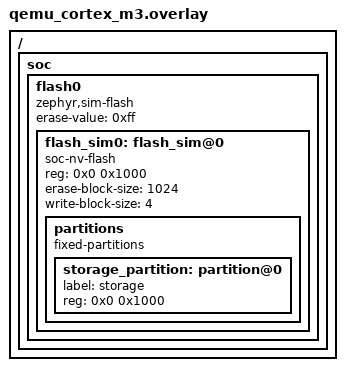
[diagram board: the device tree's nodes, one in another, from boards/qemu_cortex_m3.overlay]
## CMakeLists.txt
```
cmake_minimum_required(VERSION 3.20.0)

find_package(Zephyr REQUIRED HINTS $ENV{ZEPHYR_BASE})
project(test)

add_compile_definitions(CONFIG_CTR_CLOUD_LOG_LEVEL=4)
add_compile_definitions(CONFIG_CTR_CLOUD_TRANSFER_BUF_SIZE=16384)

include_directories(${CMAKE_CURRENT_SOURCE_DIR}/../../../subsys/ctr_cloud)
target_sources(app PRIVATE ${CMAKE_CURRENT_SOURCE_DIR}/../../../subsys/ctr_cloud/ctr_cloud_packet.c)
target_sources(app PRIVATE ${CMAKE_CURRENT_SOURCE_DIR}/../../../subsys/ctr_cloud/ctr_cloud_msg.c)
target_sources(app PRIVATE ${CMAKE_CURRENT_SOURCE_DIR}/../../../subsys/ctr_cloud/ctr_cloud_transfer.c)
target_sources(app PRIVATE ${CMAKE_CURRENT_SOURCE_DIR}/../../../subsys/ctr_cloud/ctr_cloud_util.c)
target_sources(app PRIVATE ${CMAKE_CURRENT_SOURCE_DIR}/../../../subsys/ctr_cloud/ctr_cloud_process.c)
target_sources(app PRIVATE ${CMAKE_CURRENT_SOURCE_DIR}/../../../subsys/ctr_cloud/ctr_cloud_shell.c)
target_sources(app PRIVATE ${CMAKE_CURRENT_SOURCE_DIR}/../../../subsys/ctr_cloud/ctr_cloud.c)

target_sources(app PRIVATE src/mock.c)
target_sources(app PRIVATE src/mock_ctr_info.c)
target_sources(app PRIVATE src/mock_ctr_lte_v2.c)
target_sources(app PRIVATE src/mock_ctr_rtc.c)

target_sources(app PRIVATE src/test_packet.c)
target_sources(app PRIVATE src/test_msg.c)

# target_sources(app PRIVATE src/test_cloud.c)
```

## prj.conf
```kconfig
CONFIG_LOG=y

CONFIG_EVENTS=y

CONFIG_SHELL=y
CONFIG_SHELL_LOG_BACKEND=n
CONFIG_SHELL_BACKEND_SERIAL=n
CONFIG_SHELL_BACKEND_DUMMY=y
CONFIG_SHELL_CMD_BUFF_SIZE=90
CONFIG_SHELL_BACKEND_DUMMY_BUF_SIZE=4096

CONFIG_CTR_BUF=y
CONFIG_CTR_UTIL=y
CONFIG_CTR_CONFIG=y
CONFIG_CTR_CONFIG_FACTORY_RESET=n
CONFIG_BASE64=y

CONFIG_SETTINGS=y
CONFIG_SETTINGS_FILE=y

CONFIG_ZCBOR=y
CONFIG_ZCBOR_STOP_ON_ERROR=y
CONFIG_ZCBOR_VERBOSE=n

CONFIG_ZTEST=y

CONFIG_HEAP_MEM_POOL_SIZE=256
CONFIG_MAIN_STACK_SIZE=2048

CONFIG_REBOOT=y

# PSA crypto API (backend selection is per-board; see boards/*.conf)
CONFIG_PSA_WANT_ALG_SHA_256=y
```

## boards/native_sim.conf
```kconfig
CONFIG_FLASH_SIMULATOR=y
CONFIG_FLASH=y
CONFIG_FLASH_MAP=y

# native_sim has a CSPRNG-capable entropy driver, so the Mbed TLS PSA
# provider works without the external-RNG fallback. On this non-Nordic target
# PSA_CRYPTO selects the Mbed TLS provider (CONFIG_PSA_CRYPTO_PROVIDER_MBEDTLS).
CONFIG_PSA_CRYPTO=y
CONFIG_ENTROPY_GENERATOR=y
```

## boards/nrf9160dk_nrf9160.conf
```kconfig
CONFIG_FLASH=y
CONFIG_FLASH_MAP=y

# nRF targets use the nRF Security PSA backend (CryptoCell / Oberon).
# On Nordic ARM, PSA_CRYPTO selects CONFIG_PSA_CRYPTO_PROVIDER_CUSTOM, which
# auto-enables NRF_SECURITY and MBEDTLS_PSA_CRYPTO_C.
CONFIG_PSA_CRYPTO=y
```

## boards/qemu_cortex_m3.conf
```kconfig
CONFIG_FLASH_SIMULATOR=y
CONFIG_FLASH=y
CONFIG_FLASH_MAP=y

# qemu_cortex_m3 has no CSPRNG / entropy driver, so use the Mbed TLS PSA
# provider with the external (non-CSPRNG) RNG. This is fine for tests.
CONFIG_PSA_CRYPTO=y
CONFIG_MBEDTLS_PSA_CRYPTO_EXTERNAL_RNG=y
CONFIG_MBEDTLS_PSA_CRYPTO_EXTERNAL_RNG_ALLOW_NON_CSPRNG=y
CONFIG_TEST_RANDOM_GENERATOR=y
```

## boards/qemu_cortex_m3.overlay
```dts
/ {
	soc {
		flash0 {
			compatible = "zephyr,sim-flash";
			status = "okay";
			erase-value = <0xff>;
			#address-cells = <1>;
			#size-cells = <1>;

			flash_sim0: flash_sim@0 {
				compatible = "soc-nv-flash";
				reg = <0x0 0x1000>;

				erase-block-size = <1024>;
				write-block-size = <4>;

				partitions {
					compatible = "fixed-partitions";
					#address-cells = <1>;
					#size-cells = <1>;

					storage_partition: partition@0 {
						label = "storage";
						reg = <0x0 0x1000>;
					};
				};
			};
		};
	};
};
```

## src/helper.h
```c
#ifndef TESTS_SUBSYS_CTR_CLOUD_SRC_HELPER_H_
#define TESTS_SUBSYS_CTR_CLOUD_SRC_HELPER_H_

#define PRINT_CTR_BUF(_name)                                                                       \
	printf("buffer: ");                                                                        \
	for (int i = 0; i < _name.len; i++) {                                                      \
		printf("%02x", _name.mem[i]);                                                      \
	}                                                                                          \
	printf("\n");

#endif
```

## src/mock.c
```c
#include "mock.h"

/* Standard includes */
#include <ctype.h>
#include <stdbool.h>
#include <stdlib.h>
#include <string.h>

/* Zephyr includes */
#include <zephyr/kernel.h>
#include <zephyr/settings/settings.h>
#include <zephyr/shell/shell.h>
#include <zephyr/shell/shell_dummy.h>
#include <zephyr/ztest.h>

/* Chester includes */
#include <chester/ctr_config.h>

struct app_config {
	int interval_sample;
	int interval_report;
	bool backup_report_connected;
};

static struct app_config m_app_config_interim = {
	.interval_sample = 5,
	.interval_report = 60,
	.backup_report_connected = false,
};

// void sys_arch_reboot(int type)
// {
// 	printf("sys_arch_reboot: %d\n", type);
// }

static int app_config_cmd_config_show(const struct shell *shell, size_t argc, char **argv)
{
	shell_print(shell, "app config interval-sample %d", m_app_config_interim.interval_sample);
	shell_print(shell, "app config interval-report %d", m_app_config_interim.interval_report);
	shell_print(shell, "app config backup-report-connected %s",
		    m_app_config_interim.backup_report_connected ? "true" : "false");
	return 0;
}

void *mock_global_setup_suite(void)
{
	static bool is_setup = false;

	printf("mock_global_setup_suite: %d\n", is_setup);

	if (is_setup) {
		return NULL;
	}

	// Wait for the initialization of the shell dummy backend
	const struct shell *sh = shell_backend_dummy_get_ptr();
	WAIT_FOR(shell_ready(sh), 20000, k_msleep(1));
	zassert_true(shell_ready(sh), "timed out waiting for dummy shell backend");

	// Register callbacks for the `config show` command
	ctr_config_append_show("app", app_config_cmd_config_show);

	is_setup = true;

	return NULL;
}

int app_config_cmd_config_interval_sample(const struct shell *shell, size_t argc, char **argv)
{
	if (argc == 2) {
		int interval_sample = atoi(argv[1]);

		if (interval_sample < 5 || interval_sample > 3600) {
			shell_error(shell, "invalid range");
			return -EINVAL;
		}

		m_app_config_interim.interval_sample = interval_sample;

		return 0;
	}

	shell_help(shell);
	return -EINVAL;
}

int app_config_cmd_config_interval_report(const struct shell *shell, size_t argc, char **argv)
{
	if (argc == 2) {
		int interval_report = atoi(argv[1]);

		if (interval_report < 30 || interval_report > 86400) {
			shell_error(shell, "invalid range");
			return -EINVAL;
		}

		m_app_config_interim.interval_report = interval_report;

		return 0;
	}

	shell_help(shell);
	return -EINVAL;
}

int app_config_cmd_config_backup_report_connected(const struct shell *shell, size_t argc,
						  char **argv)
{
	if (argc == 2) {
		bool is_false = !strcmp(argv[1], "false");
		bool is_true = !strcmp(argv[1], "true");

		if (is_false) {
			m_app_config_interim.backup_report_connected = false;
		} else if (is_true) {
			m_app_config_interim.backup_report_connected = true;
		} else {
			shell_error(shell, "invalid format");
			return -EINVAL;
		}

		return 0;
	}

	shell_help(shell);
	return -EINVAL;
}

static int print_help(const struct shell *shell, size_t argc, char **argv)
{
	if (argc > 1) {
		shell_error(shell, "command not found: %s", argv[1]);
		shell_help(shell);
		return -EINVAL;
	}

	shell_help(shell);

	return 0;
}

SHELL_STATIC_SUBCMD_SET_CREATE(
	sub_app_config,

	SHELL_CMD_ARG(show, NULL, "List current configuration.", app_config_cmd_config_show, 1, 0),

	SHELL_CMD_ARG(interval-sample, NULL,
		      "Get/Set sample interval in seconds (format: <5-3600>).",
		      app_config_cmd_config_interval_sample, 1, 1),

	SHELL_CMD_ARG(interval-report, NULL,
		      "Get/Set report interval in seconds (format: <30-86400>).",
		      app_config_cmd_config_interval_report, 1, 1),

	SHELL_CMD_ARG(backup-report-connected, NULL,
		      "Get/Set report when backup is active (format: true, false).",
		      app_config_cmd_config_backup_report_connected, 1, 1),

	SHELL_SUBCMD_SET_END);

SHELL_STATIC_SUBCMD_SET_CREATE(sub_app,

			       SHELL_CMD_ARG(config, &sub_app_config, "Configuration commands.",
					     print_help, 1, 0),

			       SHELL_SUBCMD_SET_END);

SHELL_CMD_REGISTER(app, &sub_app, "Application commands.", print_help);
```

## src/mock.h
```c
#ifndef TESTS_SUBSYS_CTR_CLOUD_SRC_MOCK_H_
#define TESTS_SUBSYS_CTR_CLOUD_SRC_MOCK_H_

void *mock_global_setup_suite(void);

void mock_ctr_lte_v2_set_send_recv(char **list, int size);

#endif
```

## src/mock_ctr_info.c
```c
#include <chester/ctr_info.h>

int ctr_info_get_vendor_name(char **vendor_name)
{
	static char name[] = "HARDWARIO";
	*vendor_name = name;
	return 0;
}

int ctr_info_get_product_name(char **product_name)
{
	static char name[] = "CHESTER-M";
	*product_name = name;
	return 0;
}

int ctr_info_get_hw_variant(char **hw_variant)
{
	static char variant[] = "CGLS";
	*hw_variant = variant;
	return 0;
}
int ctr_info_get_hw_revision(char **hw_revision)
{
	static char revision[] = "R3.2";
	*hw_revision = revision;
	return 0;
}

int ctr_info_get_fw_bundle(char **fw_bundle)
{
	static char bundle[] = "com.hardwario.mockup-app";
	*fw_bundle = bundle;
	return 0;
}

int ctr_info_get_fw_name(char **fw_name)
{
	static char name[] = "mockup-app";
	*fw_name = name;
	return 0;
}

int ctr_info_get_fw_version(char **fw_version)
{
	static char version[] = "v0.0.1";
	*fw_version = version;
	return 0;
}

int ctr_info_get_serial_number_uint32(uint32_t *serial_number)
{
	*serial_number = 2159017985;
	return 0;
}

int ctr_info_get_claim_token(char **claim_token)
{
	static char token[] = "98a8856ba6534bd5212176b22f3acbb3";
	*claim_token = token;
	return 0;
}

int ctr_info_get_ble_passkey(char **ble_passkey)
{
	static char passkey[] = "654123";
	*ble_passkey = passkey;
	return 0;
}
```

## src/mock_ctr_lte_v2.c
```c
#include "mock.h"

#include <zephyr/kernel.h>
#include <zephyr/ztest.h>

#include <chester/ctr_buf.h>
#include <chester/ctr_lte_v2.h>
#include <ctr_cloud_packet.h>

static bool is_enabled = false;

int ctr_lte_v2_enable(void)
{
	is_enabled = true;
	return 0;
}

int ctr_lte_v2_wait_for_connected(k_timeout_t timeout)
{
	if (!is_enabled) {
		return -1;
	}

	return 0;
}

int ctr_lte_v2_get_imei(uint64_t *imei)
{
	*imei = 987654321098761;
	return 0;
}

int ctr_lte_v2_get_imsi(uint64_t *imsi)
{
	*imsi = 123456789012341;
	return 0;
}

int ctr_lte_v2_get_iccid(char **iccid)
{
	static char iccid_str[] = "89882390000262826558";
	*iccid = iccid_str;
	return 0;
}

int ctr_lte_v2_get_modem_fw_version(char **version)
{
	*version = "v1.5.0";
	return 0;
}

void print_bufer(uint8_t *buf, size_t len)
{
	for (int i = 0; i < len; i++) {
		printf("%02x", buf[i]);
	}
	printf("\n");
}

static struct {
	int index;
	int size;
	char **list;

	uint8_t recv[CTR_CLOUD_PACKET_MAX_SIZE];
} mock_com;

void mock_ctr_lte_v2_set_send_recv(char **list, int size)
{
	mock_com.index = 0;
	mock_com.size = size;
	mock_com.list = list;
}

int ctr_lte_v2_send_recv(const struct ctr_lte_v2_send_recv_param *param)
{
	printf("mock: ctr_lte_v2_send_recv %d\n", mock_com.index);

	for (size_t i = 0; i < param->send_len; i++) {
		printf("%02x", ((uint8_t *)param->send_buf)[i]);
	}
	printf("\n");

	if (mock_com.index >= mock_com.size) {
		return -1;
	}

	char *recvStr = mock_com.list[mock_com.index++];

	hex2bin(recvStr, strlen(recvStr), mock_com.recv, sizeof(mock_com.recv));

	zassert_mem_equal(mock_com.recv, param->send_buf, param->send_len, NULL);

	char *sendStr = mock_com.list[mock_com.index++];
	*param->recv_len = 0;

	if (sendStr != NULL && param->recv_buf) {
		*param->recv_len =
			hex2bin(sendStr, strlen(sendStr), param->recv_buf, param->recv_size);
	}

	return 0;
}

int ctr_lte_v2_get_conn_param(struct ctr_lte_v2_conn_param *param)
{
	param->valid = true;
	param->result = 0;
	param->ecl = 12;
	param->rsrp = 13;
	param->rsrq = 14;
	param->snr = 15;
	param->plmn = 16;
	param->cid = 17;
	param->band = 18;
	param->earfcn = 19;
	return 0;
}
```

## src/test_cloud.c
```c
/** @file
 *  @brief cloud transfere test suite
 */

#include "mock.h"

#include <zephyr/kernel.h>
#include <zephyr/settings/settings.h>
#include <zephyr/ztest.h>
#include <zephyr/shell/shell.h>
#include <zephyr/shell/shell_dummy.h>

#include <chester/ctr_buf.h>
#include <chester/ctr_cloud.h>
#include <ctr_cloud_packet.h>
#include <ctr_cloud_msg.h>
#include <ctr_cloud_util.h>

ZTEST(subsus_ctr_cloud_2_cloud, test_boot)
{
	int ret;

	static char *comunication[] = {
		// send: Sequence: 0 [FLxx] len: 128 / upload session
		"422941fa2c33723f80b00001c00000bf0000101a80b00001016948415244574152494f026943484553"
		"5445522d4d036443474c53046452332e32057818636f6d2e68617264776172696f2e6d6f636b75702d"
		"617070066a6d6f636b75702d617070076676302e302e3108663635343132330a1b0003824430f85009"
		"091b00007048860ddf750b6676312e352e30ff",
		// recv: Sequence: 1 [xxAP] len: 0 / ack + signal poll
		"49247ac38dacbbf280b000013001",
		// send: Sequence: 2 [xxxP] len: 0 / poll
		"98b2f3d80b97ac9280b000011002",
		// recv: Sequence: 3 [FLxx] len: 73 / download session
		"9d810702bd57739980b00001c00380a4001a64ba538f041a64ba538e05782430313838643835632d38"
		"3936322d373836662d633938352d6136376665653762623134340672746573742d6465766963652d73"
		"302d393835",
		// send: Sequence: 4 [xxAx] len: 0 / ack
		"7cf1efb80c99381780b000012004",
		// no recv
		NULL,
		// send: Sequence: 5 [FLxx] len: 115 / upload config
		"ffd664838db07ee980b00001c0050273a9151b127641bb009f781c61707020636f6e66696720696e74"
		"657276616c2d73616d706c652035781d61707020636f6e66696720696e74657276616c2d7265706f72"
		"74203630782861707020636f6e666967206261636b75702d7265706f72742d636f6e6e656374656420"
		"66616c7365ff",
		// recv: equence: 6 [xxAP] len: 0 / ack + signal poll
		"0842b756691c629f80b000013006",
		// send: Sequence: 7 [xxxP] len: 0 / poll
		"945af7019589847480b000011007",
		// recv: Sequence: 8 [FLxx] len: 106 / download config
		"d2ea74f6a898857880b00001c008820083781d61707020636f6e66696720696e74657276616c2d7361"
		"6d706c65203130781d61707020636f6e66696720696e74657276616c2d7265706f7274203630782761"
		"707020636f6e666967206261636b75702d7265706f72742d636f6e6e65637465642074727565",
		// send: Sequence: 9 [xxAx] len: 0 / ack
		"80e388a08e84beb080b000012009",
		// no recv
		NULL,
		// send: Sequence: 10 [xxxP] len: 0
		"cb4bb2d99e3a56e680b00001100a",
		// recv: Sequence: 11 [FLxx] len: 0
		"7bc147fda33d7aee80b00001c00b",
		// send: packet Sequence: 12 [xxxP] len: 0
		"ae81ae8eeedbd27180b00001100c",
		// recv: Sequence: 13 [FLxx] len: 66 / download shell
		"76e10e221e84573080b00001c00d87a200826f61707020636f6e6669672073686f77781a6170702063"
		"6f6e66696720696e74657276616c2d73616d706c650150018dd0f29d0175f2abaf092b8d2f9f2b",
		// send: Sequence: 14 [xxAx] len: 0
		"5eded0b6ce8631e880b00001200e",
		NULL,
		// send: Sequence: 15 [FLxx] len: 259 / upload shell
		"327c0f4de53ae7ed80b00001c00f07bf0150018dd0f29d0175f2abaf092b8d2f9f2b009fbf006f6170"
		"7020636f6e6669672073686f77029f781d61707020636f6e66696720696e74657276616c2d73616d70"
		"6c65203130781d61707020636f6e66696720696e74657276616c2d7265706f72742036307827617070"
		"20636f6e666967206261636b75702d7265706f72742d636f6e6e65637465642074727565ffffbf0078"
		"1a61707020636f6e66696720696e74657276616c2d73616d706c650135029f7848696e74657276616c"
		"2d73616d706c65202d204765742f5365742073616d706c6520696e74657276616c20696e207365636f"
		"6e64732028666f726d61743a203c352d333630303e292effffffff",
		// recv: Sequence: 16 [xxAx] len: 0
		"ca3e3abdaf98f36880b000012010",
		NULL,
	};

	mock_ctr_lte_v2_set_send_recv(comunication, sizeof(comunication) / sizeof(comunication[0]));

	static struct ctr_cloud_options options = {
		.decoder_hash = 0,
		.encoder_hash = 0,
		.decoder_buf = NULL,
		.decoder_len = 0,
		.encoder_buf = NULL,
		.encoder_len = 0,
	};

	int64_t ts;

	// ret = ctr_cloud_get_last_seen_ts(&ts);
	// zassert_equal(ret, -EPERM, "ctr_cloud_get_last_seen_ts failed");

	ret = ctr_cloud_init(&options);
	zassert_ok(ret, "ctr_cloud_init failed");

	ret = ctr_cloud_wait_initialized(K_MSEC(2000));
	zassert_ok(ret, "ctr_cloud_wait_initialized failed");

	ret = ctr_cloud_get_last_seen_ts(&ts);
	zassert_ok(ret, "ctr_cloud_get_last_seen_ts");

	zassert_equal(ts, 1689932686, "last downlink ts");

	printf("\ntest: last downlink ts: %lld\n", ts);

	ctr_cloud_downlink(K_FOREVER); // poll without data
	ctr_cloud_downlink(K_FOREVER); // poll shell

	k_sleep(K_MSEC(300));
}

// ZTEST(subsus_ctr_cloud_2_cloud, test_app_fw)
// {
// 	int ret;

// 	static char *comunication[] = {
// 		// send: Sequence: 0 [FLxx] len: 128 / upload session
// 		"422941fa2c33723f80b00001c00000bf0000101a80b00001016948415244574152494f026943484553"
// 		"5445522d4d036443474c53046452332e32057818636f6d2e68617264776172696f2e6d6f636b75702d"
// 		"617070066a6d6f636b75702d617070076676302e302e3108663635343132330a1b0003824430f85009"
// 		"091b00007048860ddf750b6676312e352e30ff",
// 		// recv: Sequence: 1 [xxAP] len: 0 / ack + signal poll
// 		"49247ac38dacbbf280b000013001",
// 		// send: Sequence: 2 [xxxP] len: 0 / poll
// 		"98b2f3d80b97ac9280b000011002",
// 		// recv: Sequence: 3 [FLxx] len: 93 / download session
// 		"ea9c3efa69351cef80b00001c00380a6001a65e62f3d021b46c3ba674e0f604f031b73a9151b127641"
// 		"bb041a65e62f3c05782430313838643835632d383936322d373836662d633938352d61363766656537"
// 		"62623134340672746573742d6465766963652d73302d393835",
// 		// send: Sequence: 4 [xxAx] len: 0 / ack
// 		"7cf1efb80c99381780b000012004",
// 		// no recv
// 		NULL,
// 		// Sequence: 5 [xxxP] len: 0
// 		"8518c99e482c211680b000011005",
// 		// Sequence: 6 [FLxx] len: 0
// 		"fdca48f52dcd34e580b00001c006",
// 		// Sequence: 7 [FLxx] len: 57 / upload firmware app start
// 		"d525afc2f3d822eb80b00001c00708bf00636170700168646f776e6c6f616404193f00057820613861"
// 		"3839663530386130383462323239393634316266346135306636356564ff",
// 		// Sequence: 8 [xxAP] len: 0
// 		"f595fffcda87190080b000013008",
// 		// Sequence: 9 [xxxP] len: 0
// 		"e4033647654ea95f80b000011009",
// 		// Sequence: 10 [FLxx] len: 73 // download firmware chunk offset 0
// 		"2f378122505c8de480b00001c00a88a7006361707001656368756e6b0250018e39b69e7d73d68497b2"
// 		"9fb053ba20030004181e05581eaabbccddee00112233445566778899aabbccddee0011223344556677"
// 		"889906181e",
// 		// Sequence: 11 [xxAx] len: 0
// 		"c858daa739bdd2fb80b00001200b",
// 		// no recv
// 		NULL,
// 	};
// 	mock_ctr_lte_v2_set_send_recv(comunication, sizeof(comunication) / sizeof(comunication[0]));

// 	static struct ctr_cloud_options options = {
// 		.decoder_hash = 0,
// 		.encoder_hash = 0,
// 		.decoder_buf = NULL,
// 		.decoder_len = 0,
// 		.encoder_buf = NULL,
// 		.encoder_len = 0,
// 	};

// 	ret = ctr_cloud_init(&options);
// 	zassert_ok(ret, "ctr_cloud_init failed");

// 	ret = ctr_cloud_wait_initialized(K_MSEC(2000));
// 	zassert_ok(ret, "ctr_cloud_wait_initialized failed");

// 	ctr_cloud_recv(); // poll without data

// 	const struct shell *sh = shell_backend_dummy_get_ptr();
// 	shell_backend_dummy_clear_output(sh);
// 	ret = shell_execute_cmd(sh, "cloud firmware download a8a89f508a084b2299641bf4a50f65ed");
// 	// zassert_ok(ret, "shell_execute_cmd failed");
// 	size_t size;
// 	const char *p = shell_backend_dummy_get_output(sh, &size);
// 	zassert_not_null(p, "shell_backend_dummy_get_output failed");

// 	printf("\n%s\n", p);

// 	k_sleep(K_MSEC(500));
// }

ZTEST_SUITE(subsus_ctr_cloud_2_cloud, NULL, mock_global_setup_suite, NULL, NULL, NULL);
```

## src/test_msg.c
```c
/** @file
 *  @brief cloud message test suite
 *
 */

#include "helper.h"
#include "mock.h"

#include <zephyr/kernel.h>
#include <zephyr/ztest.h>
#include <zephyr/settings/settings.h>

#include <chester/ctr_buf.h>
#include <ctr_cloud_msg.h>
#include <ctr_cloud_util.h>

ZTEST(subsus_ctr_cloud_1_msg, test_pack_create_session)
{
	CTR_BUF_DEFINE(buffer, 512);

	int ret = ctr_cloud_msg_pack_create_session(&buffer);
	zassert_ok(ret, "ctr_cloud_msg_pack_create_session failed");

	char *expectHex =
		"00bf0000101a80b00001016948415244574152494f0269434845535445522d4d036443474c53046452"
		"332e32057818636f6d2e68617264776172696f2e6d6f636b75702d617070066a6d6f636b75702d6170"
		"70076676302e302e3108663635343132330a1b0003824430f85009091b00007048860ddf7511743839"
		"3838323339303030303236323832363535380b6676312e352e30ff";

	// PRINT_CTR_BUF(buffer);

	CTR_BUF_DEFINE(expect, 512);

	expect.len = hex2bin(expectHex, strlen(expectHex), expect.mem, expect.size);

	zassert_equal(buffer.len, expect.len, "len equal");
	zassert_mem_equal(buffer.mem, expect.mem, expect.len, "mem equal");
}

ZTEST(subsus_ctr_cloud_1_msg, test_unpack_set_session)
{
	CTR_BUF_DEFINE(buffer, 512);

	char *input = "80a6001a649e9358011b1fbe3ac758c6f88c021b46c3ba674e0f604f041a649e935905782430"
		      "313839306236362d633866352d373065612d396634332d61666532346564663966353506696b"
		      "6172656c2d646576";

	buffer.len = hex2bin(input, strlen(input), buffer.mem, buffer.size);

	struct ctr_cloud_session session;

	int ret = ctr_cloud_msg_unpack_set_session(&buffer, &session);
	zassert_ok(ret, "ctr_cloud_msg_unpack_set_session failed");

	zassert_equal(session.id, (uint32_t)1688114008, "id");
	zassert_equal(session.decoder_hash, (uint64_t)0x1fbe3ac758c6f88c, "decoder_hash");
	zassert_equal(session.encoder_hash, (uint64_t)0x46c3ba674e0f604f, "encoder_hash");
	zassert_equal(session.config_hash, 0, "config_hash");
	zassert_true(strcmp(session.device_id, "01890b66-c8f5-70ea-9f43-afe24edf9f55") == 0, "id");
	zassert_true(strcmp(session.device_name, "karel-dev") == 0, "name");
}

ZTEST(subsus_ctr_cloud_1_msg, test_pack_get_timestamp)
{
	CTR_BUF_DEFINE(buffer, 512);

	int ret = ctr_cloud_msg_pack_get_timestamp(&buffer);
	zassert_ok(ret, "ctr_cloud_msg_pack_get_timestamp failed");

	uint8_t expect[] = {0x01};

	zassert_equal(buffer.len, 1, "len equal");
	zassert_mem_equal(buffer.mem, expect, 1, "mem equal");
}

ZTEST(subsus_ctr_cloud_1_msg, test_unpack_set_timestamp)
{
	CTR_BUF_DEFINE(buffer, 512);

	char *input = "8100000000648d56b9";

	buffer.len = hex2bin(input, strlen(input), buffer.mem, buffer.size);

	int64_t ts;

	int ret = ctr_cloud_msg_unpack_set_timestamp(&buffer, &ts);
	zassert_ok(ret, "ctr_cloud_msg_unpack_set_timestamp failed");

	zassert_equal(ts, (int64_t)1686984377, "ts");
}

ZTEST(subsus_ctr_cloud_1_msg, test_pack_stats)
{
	CTR_BUF_DEFINE(buffer, 512);

	int ret = ctr_cloud_msg_pack_stats(&buffer);
	zassert_ok(ret, "ctr_cloud_msg_pack_stats failed");
	// TODO: check the output
}

ZTEST(subsus_ctr_cloud_1_msg, test_pack_config)
{
	CTR_BUF_DEFINE(buffer, 512);

	int ret = ctr_cloud_msg_pack_config(&buffer);
	zassert_ok(ret, "ctr_cloud_msg_pack_config failed");

	char *expectHex =
		"0273a9151b127641bb009f781c61707020636f6e66696720696e74657276616c2d73616d706c652035"
		"781d61707020636f6e66696720696e74657276616c2d7265706f7274203630782861707020636f6e66"
		"6967206261636b75702d7265706f72742d636f6e6e65637465642066616c7365ff";

	CTR_BUF_DEFINE(expect, 512);

	// PRINT_CTR_BUF(buffer);

	expect.len = hex2bin(expectHex, strlen(expectHex), expect.mem, expect.size);

	zassert_equal(buffer.len, expect.len, "len equal");
	zassert_mem_equal(buffer.mem, expect.mem, expect.len, "mem equal");

	uint64_t hash_expect = 0x73a9151b127641bb;
	uint64_t hash;
	ctr_cloud_msg_get_hash(&buffer, &hash);

	zassert_equal(hash, hash_expect, "hash equal");
}

ZTEST(subsus_ctr_cloud_1_msg, test_unpack_download_config)
{
	CTR_BUF_DEFINE(buffer, 512);

	char *input = "820083781d61707020636f6e66696720696e74657276616c2d73616d706c65203130781d6170"
		      "7020636f6e66696720696e74657276616c2d7265706f7274203630782761707020636f6e6669"
		      "67206261636b75702d7265706f72742d636f6e6e65637465642074727565";

	buffer.len = hex2bin(input, strlen(input), buffer.mem, buffer.size);

	struct ctr_cloud_msg_dlconfig config;

	int ret = ctr_cloud_msg_unpack_config(&buffer, &config);
	zassert_ok(ret, "ctr_cloud_msg_unpack_config failed");

	zassert_equal(config.lines, 3, "lines");

	CTR_BUF_DEFINE(line, CONFIG_SHELL_CMD_BUFF_SIZE + 1);

	ctr_buf_reset(&line);
	ret = ctr_cloud_msg_dlconfig_get_next_line(&config, &line);
	zassert_ok(ret, "ctr_cloud_msg_dlconfig_get_next_line failed");

	zassert_true(strcmp(line.mem, "app config interval-sample 10") == 0, "line 1");

	ctr_buf_reset(&line);
	ret = ctr_cloud_msg_dlconfig_get_next_line(&config, &line);
	zassert_ok(ret, "ctr_cloud_msg_dlconfig_get_next_line failed");

	zassert_true(strcmp(line.mem, "app config interval-report 60") == 0, "line 2");

	ctr_buf_reset(&line);
	ret = ctr_cloud_msg_dlconfig_get_next_line(&config, &line);
	zassert_ok(ret, "ctr_cloud_msg_dlconfig_get_next_line failed");

	zassert_true(strcmp(line.mem, "app config backup-report-connected true") == 0, "line 3");

	ret = ctr_cloud_msg_dlconfig_get_next_line(&config, &line);
	zassert_equal(ret, -ENODATA, "ctr_cloud_msg_dlconfig_get_next_line failed");
}

ZTEST(subsus_ctr_cloud_1_msg, test_unpack_download_shell)
{
	CTR_BUF_DEFINE(buffer, 512);

	char *input = "87a200826f61707020636f6e6669672073686f77781a61707020636f6e66696720696e746572"
		      "76616c2d73616d706c650150018dd0f29d0175f2abaf092b8d2f9f2b";

	buffer.len = hex2bin(input, strlen(input), buffer.mem, buffer.size);

	struct ctr_cloud_msg_dlshell dlshell;

	int ret = ctr_cloud_msg_unpack_dlshell(&buffer, &dlshell);

	printf("ret: %d\n", ret);

	zassert_ok(ret, "ctr_cloud_msg_unpack_dlshell failed");
	zassert_equal(dlshell.commands, 2, "cmds len");

	char uuid[37];

	ret = ctr_cloud_util_uuid_to_str(dlshell.message_id, uuid, sizeof(uuid));

	printf("uuid: %s\n", uuid);

	ctr_cloud_uuid_t message_id = {0x01, 0x8d, 0xd0, 0xf2, 0x9d, 0x01, 0x75, 0xf2,
				       0xab, 0xaf, 0x09, 0x2b, 0x8d, 0x2f, 0x9f, 0x2b};
	zassert_mem_equal(dlshell.message_id, message_id, sizeof(ctr_cloud_uuid_t), "uuid equal");

	CTR_BUF_DEFINE(command, CONFIG_SHELL_CMD_BUFF_SIZE + 1);

	ctr_buf_reset(&command);
	ret = ctr_cloud_msg_dlshell_get_next_command(&dlshell, &command);
	zassert_ok(ret, "ctr_cloud_msg_dlshell_get_next_command failed");
	zassert_true(strcmp(command.mem, "app config show") == 0, "command 1");

	ctr_buf_reset(&command);
	ret = ctr_cloud_msg_dlshell_get_next_command(&dlshell, &command);
	zassert_ok(ret, "ctr_cloud_msg_dlshell_get_next_command failed");
	zassert_true(strcmp(command.mem, "app config interval-sample") == 0, "command 2");
}

ZTEST(subsus_ctr_cloud_1_msg, test_pack_upload_shell)
{
	CTR_BUF_DEFINE(buffer, 512);

	ctr_cloud_uuid_t message_id = {0x01, 0x8d, 0xd0, 0xf2, 0x9d, 0x01, 0x75, 0xf2,
				       0xab, 0xaf, 0x09, 0x2b, 0x8d, 0x2f, 0x9f, 0x2b};

	int ret;
	struct ctr_cloud_msg_upshell upshell;

	ret = ctr_cloud_msg_pack_upshell_start(&upshell, &buffer, message_id);
	zassert_ok(ret, "ctr_cloud_msg_pack_upshell failed");

	ret = ctr_cloud_msg_pack_upshell_add_response(&upshell, "help", 0,
						      "\r\nout help\r\napp\r\nconfig\r\n");
	zassert_ok(ret, "ctr_cloud_msg_pack_upshell failed");

	ret = ctr_cloud_msg_pack_upshell_add_response(&upshell, "app", -22, "\r\nerror\r\n");
	zassert_ok(ret, "ctr_cloud_msg_pack_upshell failed");

	ret = ctr_cloud_msg_pack_upshell_end(&upshell);
	zassert_ok(ret, "ctr_cloud_msg_pack_upshell failed");

	// PRINT_CTR_BUF(buffer);

	char *expectHex =
		"07bf0150018dd0f29d0175f2abaf092b8d2f9f2b009fbf006468656c70029f686f75742068656c7063"
		"61707066636f6e666967ffffbf00636170700135029f656572726f72ffffffff";

	CTR_BUF_DEFINE(expect, 512);

	expect.len = hex2bin(expectHex, strlen(expectHex), expect.mem, expect.size);

	zassert_equal(buffer.len, expect.len, "len equal");
	zassert_mem_equal(buffer.mem, expect.mem, expect.len, "mem equal");
}

ZTEST(subsus_ctr_cloud_1_msg, test_pack_upload_firmware_app_download)
{
	CTR_BUF_DEFINE(buffer, 512);

	const char *frimware = "firmware:v1.0.0";

	struct ctr_cloud_upfirmware upfirmware = {
		.target = "app", .type = "download", .max_length = 1024, .firmware = frimware};

	int ret = ctr_cloud_msg_pack_firmware(&buffer, &upfirmware);

	zassert_ok(ret, "ctr_cloud_msg_pack_firmware failed");

	PRINT_CTR_BUF(buffer);

	char *expectHex =
		"08bf00636170700168646f776e6c6f616404190400056f6669726d776172653a76312e302e30ff";

	CTR_BUF_DEFINE(expect, 512);

	expect.len = hex2bin(expectHex, strlen(expectHex), expect.mem, expect.size);

	zassert_equal(buffer.len, expect.len, "len equal");

	zassert_mem_equal(buffer.mem, expect.mem, expect.len, "mem equal");
}

ZTEST(subsus_ctr_cloud_1_msg, test_pack_upload_firmware_app_next)
{
	CTR_BUF_DEFINE(buffer, 512);

	// a8a89f50-8a08-4b22-9964-1bf4a50f65ed
	ctr_cloud_uuid_t id = {0xa8, 0xa8, 0x9f, 0x50, 0x8a, 0x08, 0x4b, 0x22,
			       0x99, 0x64, 0x1b, 0xf4, 0xa5, 0x0f, 0x65, 0xed};

	struct ctr_cloud_upfirmware upfirmware = {
		.target = "app", .type = "next", .id = id, .offset = 100, .max_length = 1024};

	int ret = ctr_cloud_msg_pack_firmware(&buffer, &upfirmware);

	zassert_ok(ret, "ctr_cloud_msg_pack_firmware failed");

	PRINT_CTR_BUF(buffer);

	char *expectHex =
		"08bf006361707001646e6578740250a8a89f508a084b2299641bf4a50f65ed03186404190400ff";

	CTR_BUF_DEFINE(expect, 512);

	expect.len = hex2bin(expectHex, strlen(expectHex), expect.mem, expect.size);

	zassert_equal(buffer.len, expect.len, "len equal");

	zassert_mem_equal(buffer.mem, expect.mem, expect.len, "mem equal");
}

ZTEST(subsus_ctr_cloud_1_msg, test_pack_upload_firmware_app_confirmed)
{
	CTR_BUF_DEFINE(buffer, 512);

	int ret = settings_subsys_init();
	zassert_ok(ret, "Expected settings to init");

	// a8a89f50-8a08-4b22-9964-1bf4a50f65ed
	ctr_cloud_uuid_t id = {0xa8, 0xa8, 0x9f, 0x50, 0x8a, 0x08, 0x4b, 0x22,
			       0x99, 0x64, 0x1b, 0xf4, 0xa5, 0x0f, 0x65, 0xed};

	ret = ctr_cloud_util_save_firmware_update_id(id);
	printf("\nctr_cloud_util_save_firmware_update_id ret: %d\n", ret);
	zassert_ok(ret, "ctr_cloud_util_save_firmware_update_id failed");

	ctr_cloud_uuid_t fuid;
	ret = ctr_cloud_util_get_firmware_update_id(fuid);
	zassert_ok(ret, "ctr_cloud_util_get_firmware_update_id failed");

	struct ctr_cloud_upfirmware upfirmware = {
		.target = "app",
		.type = "confirmed",
		.id = fuid,
	};

	ret = ctr_cloud_msg_pack_firmware(&buffer, &upfirmware);
	zassert_ok(ret, "ctr_cloud_msg_pack_firmware failed");

	PRINT_CTR_BUF(buffer);

	char *expectHex =
		"08bf00636170700169636f6e6669726d65640250a8a89f508a084b2299641bf4a50f65edff";

	CTR_BUF_DEFINE(expect, 512);

	expect.len = hex2bin(expectHex, strlen(expectHex), expect.mem, expect.size);

	zassert_equal(buffer.len, expect.len, "len equal");
	zassert_mem_equal(buffer.mem, expect.mem, expect.len, "mem equal");
}

ZTEST(subsus_ctr_cloud_1_msg, test_unpack_download_firmware)
{
	CTR_BUF_DEFINE(buffer, 512);

	char *input = "88a60063617070016566697273740250a8a89f508a084b2299641bf4a50f65ed04181e05581e"
		      "aabbccddee00112233445566778899aabbccddee0011223344556677889906181e";

	buffer.len = hex2bin(input, strlen(input), buffer.mem, buffer.size);

	struct ctr_cloud_msg_dlfirmware dlfirmware;

	int ret = ctr_cloud_msg_unpack_dlfirmware(&buffer, &dlfirmware);
	zassert_ok(ret, "ctr_cloud_msg_unpack_dlfirmware failed");

	// a8a89f50-8a08-4b22-9964-1bf4a50f65ed
	ctr_cloud_uuid_t id = {0xa8, 0xa8, 0x9f, 0x50, 0x8a, 0x08, 0x4b, 0x22,
			       0x99, 0x64, 0x1b, 0xf4, 0xa5, 0x0f, 0x65, 0xed};
	zassert_mem_equal(dlfirmware.id, id, sizeof(ctr_cloud_uuid_t), "id equal");

	zassert_true(strcmp(dlfirmware.target, "app") == 0, "target");
	zassert_true(strcmp(dlfirmware.type, "first") == 0, "type");

	zassert_equal(dlfirmware.offset, 0, "offset");
	zassert_equal(dlfirmware.length, 30, "length");

	zassert_equal(dlfirmware.firmware_size, 30, "firmware_size");

	// data aabbccddee00112233445566778899aabbccddee00112233445566778899
	uint8_t data[30] = {0xaa, 0xbb, 0xcc, 0xdd, 0xee, 0x00, 0x11, 0x22, 0x33, 0x44,
			    0x55, 0x66, 0x77, 0x88, 0x99, 0xaa, 0xbb, 0xcc, 0xdd, 0xee,
			    0x00, 0x11, 0x22, 0x33, 0x44, 0x55, 0x66, 0x77, 0x88, 0x99};
	zassert_mem_equal(dlfirmware.data, data, 30, "data equal");
}

ZTEST_SUITE(subsus_ctr_cloud_1_msg, NULL, mock_global_setup_suite, NULL, NULL, NULL);
```

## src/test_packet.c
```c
/** @file
 *  @brief cloud packet test suite
 *
 */

#include <zephyr/kernel.h>
#include <zephyr/ztest.h>

#include <chester/ctr_buf.h>
#include <ctr_cloud_packet.h>

/* Test unpack packet */
ZTEST(subsus_ctr_cloud_0_packet, test_unpack_a)
{
	CTR_BUF_DEFINE(buffer, CTR_CLOUD_PACKET_MAX_SIZE);

	char *input = "60d05fb58c7c550b80b0000140047273696f6e6676312e342e30";
	uint8_t claim_token[16] = {0x98, 0xa8, 0x85, 0x6b, 0xa6, 0x53, 0x4b, 0xd5,
				   0x21, 0x21, 0x76, 0xb2, 0x2f, 0x3a, 0xcb, 0xb3};
	buffer.len = hex2bin(input, strlen(input), buffer.mem, buffer.size);
	struct ctr_cloud_packet pck;

	int ret = ctr_cloud_packet_unpack(&pck, claim_token, &buffer);

	zassert_ok(ret, "ctr_cloud_packet_unpack failed");
	zassert_equal(pck.serial_number, 2159017985, "serial_number not equal");
	zassert_equal(pck.sequence, 4, "sequence not equal");
	zassert_equal(pck.flags, CTR_CLOUD_PACKET_FLAG_LAST, "flags not equal");
	zassert_equal(pck.data_len, 12, "data_len not equal");
	zassert_equal_ptr(pck.data, buffer.mem + CTR_CLOUD_PACKET_MIN_SIZE, "data not equal");
}

ZTEST(subsus_ctr_cloud_0_packet, test_unpack_b)
{
	CTR_BUF_DEFINE(buffer, CTR_CLOUD_PACKET_MAX_SIZE);

	char *input = "478acfb86b963d2b80b000012014";
	uint8_t claim_token[16] = {0x98, 0xa8, 0x85, 0x6b, 0xa6, 0x53, 0x4b, 0xd5,
				   0x21, 0x21, 0x76, 0xb2, 0x2f, 0x3a, 0xcb, 0xb3};
	buffer.len = hex2bin(input, strlen(input), buffer.mem, buffer.size);
	struct ctr_cloud_packet pck;

	int ret = ctr_cloud_packet_unpack(&pck, claim_token, &buffer);

	zassert_ok(ret, "ctr_cloud_packet_unpack failed");
	zassert_equal(pck.serial_number, 2159017985, "serial_number not equal");
	zassert_equal(pck.sequence, 20, "sequence not equal");
	zassert_equal(pck.flags, CTR_CLOUD_PACKET_FLAG_ACK, "flags not equal");
	zassert_equal(pck.data_len, 0, "data_len not equal");
}

ZTEST(subsus_ctr_cloud_0_packet, test_unpack_c)
{
	CTR_BUF_DEFINE(buffer, CTR_CLOUD_PACKET_MAX_SIZE);

	char *input = "ea47c658ff37f77680b000010002ffd6987da1";
	uint8_t claim_token[16] = {0x98, 0xa8, 0x85, 0x6b, 0xa6, 0x53, 0x4b, 0xd5,
				   0x21, 0x21, 0x76, 0xb2, 0x2f, 0x3a, 0xcb, 0xb3};
	buffer.len = hex2bin(input, strlen(input), buffer.mem, buffer.size);
	struct ctr_cloud_packet pck;

	int ret = ctr_cloud_packet_unpack(&pck, claim_token, &buffer);

	zassert_ok(ret, "ctr_cloud_packet_unpack failed");
	zassert_equal(pck.serial_number, 2159017985, "serial_number not equal");
	zassert_equal(pck.sequence, 2, "sequence not equal");
	zassert_equal(pck.flags, 0, "flags not equal");
	zassert_equal(pck.data_len, 5, "data_len not equal");
	zassert_equal_ptr(pck.data, buffer.mem + CTR_CLOUD_PACKET_MIN_SIZE, "data not equal");
}

ZTEST(subsus_ctr_cloud_0_packet, test_unpack_d)
{
	CTR_BUF_DEFINE(buffer, CTR_CLOUD_PACKET_MAX_SIZE);

	char *input = "a6bce7c20f32fbcd80b00001c00381000001886ccd11e5";
	uint8_t claim_token[16] = {0x98, 0xa8, 0x85, 0x6b, 0xa6, 0x53, 0x4b, 0xd5,
				   0x21, 0x21, 0x76, 0xb2, 0x2f, 0x3a, 0xcb, 0xb3};
	buffer.len = hex2bin(input, strlen(input), buffer.mem, buffer.size);
	struct ctr_cloud_packet pck;

	int ret = ctr_cloud_packet_unpack(&pck, claim_token, &buffer);

	zassert_ok(ret, "ctr_cloud_packet_unpack failed");
	zassert_equal(pck.serial_number, 2159017985, "serial_number not equal");
	zassert_equal(pck.sequence, 3, "sequence not equal");
	zassert_equal(pck.flags, CTR_CLOUD_PACKET_FLAG_FIRST | CTR_CLOUD_PACKET_FLAG_LAST,
		      "flags not equal");
	zassert_equal(pck.data_len, 9, "data_len not equal");
	zassert_equal_ptr(pck.data, buffer.mem + CTR_CLOUD_PACKET_MIN_SIZE, "data not equal");
}

ZTEST(subsus_ctr_cloud_0_packet, test_unpack_e)
{
	CTR_BUF_DEFINE(buffer, CTR_CLOUD_PACKET_MAX_SIZE);

	char *input = "49247ac38dacbbf280b000013001";
	uint8_t claim_token[16] = {0x98, 0xa8, 0x85, 0x6b, 0xa6, 0x53, 0x4b, 0xd5,
				   0x21, 0x21, 0x76, 0xb2, 0x2f, 0x3a, 0xcb, 0xb3};
	buffer.len = hex2bin(input, strlen(input), buffer.mem, buffer.size);
	struct ctr_cloud_packet pck;

	int ret = ctr_cloud_packet_unpack(&pck, claim_token, &buffer);

	zassert_ok(ret, "ctr_cloud_packet_unpack failed");
	zassert_equal(pck.serial_number, 2159017985, "serial_number not equal");
	zassert_equal(pck.sequence, 1, "sequence not equal");
	zassert_equal(pck.flags, CTR_CLOUD_PACKET_FLAG_ACK | CTR_CLOUD_PACKET_FLAG_POLL,
		      "flags not equal");
	zassert_equal(pck.data_len, 0, "data_len not equal");
}

ZTEST(subsus_ctr_cloud_0_packet, test_unpack_error_short)
{
	CTR_BUF_DEFINE(buffer, CTR_CLOUD_PACKET_MAX_SIZE);

	char *input = "49247ac38dacbbf280b000";
	uint8_t claim_token[16] = {0x98, 0xa8, 0x85, 0x6b, 0xa6, 0x53, 0x4b, 0xd5,
				   0x21, 0x21, 0x76, 0xb2, 0x2f, 0x3a, 0xcb, 0xb3};
	buffer.len = hex2bin(input, strlen(input), buffer.mem, buffer.size);
	struct ctr_cloud_packet pck;

	int ret = ctr_cloud_packet_unpack(&pck, claim_token, &buffer);

	zassert_equal(ret, -EBADMSG, "ctr_cloud_packet_unpack failed");
}

ZTEST(subsus_ctr_cloud_0_packet, test_unpack_error_bad_hash)
{
	CTR_BUF_DEFINE(buffer, CTR_CLOUD_PACKET_MAX_SIZE);

	char *input = "00247ac38dacbbf280b000013001";
	uint8_t claim_token[16] = {0x98, 0xa8, 0x85, 0x6b, 0xa6, 0x53, 0x4b, 0xd5,
				   0x21, 0x21, 0x76, 0xb2, 0x2f, 0x3a, 0xcb, 0xb3};
	buffer.len = hex2bin(input, strlen(input), buffer.mem, buffer.size);
	struct ctr_cloud_packet pck;

	int ret = ctr_cloud_packet_unpack(&pck, claim_token, &buffer);

	zassert_equal(ret, -EBADMSG, "ctr_cloud_packet_unpack failed");
}

ZTEST(subsus_ctr_cloud_0_packet, test_pack_a)
{
	CTR_BUF_DEFINE(buffer, CTR_CLOUD_PACKET_MAX_SIZE);
	ctr_buf_fill(&buffer, 0xff);

	uint8_t claim_token[16] = {0x98, 0xa8, 0x85, 0x6b, 0xa6, 0x53, 0x4b, 0xd5,
				   0x21, 0x21, 0x76, 0xb2, 0x2f, 0x3a, 0xcb, 0xb3};
	struct ctr_cloud_packet pck;

	pck.serial_number = 2159017985;
	pck.sequence = 20;
	pck.flags = CTR_CLOUD_PACKET_FLAG_ACK;
	pck.data_len = 0;

	int ret = ctr_cloud_packet_pack(&pck, claim_token, &buffer);

	zassert_ok(ret, "ctr_cloud_packet_pack failed");
	zassert_equal(buffer.len, 14, "buffer.len not equal");

	char *expected = "478acfb86b963d2b80b000012014";

	uint8_t expectedBin[14];
	hex2bin(expected, strlen(expected), expectedBin, sizeof(expectedBin));

	zassert_equal(memcmp(buffer.mem, expectedBin, buffer.len), 0, "buffer.mem not equal");
}

ZTEST(subsus_ctr_cloud_0_packet, test_pack_b)
{
	CTR_BUF_DEFINE(buffer, CTR_CLOUD_PACKET_MAX_SIZE);
	ctr_buf_fill(&buffer, 0xff);

	uint8_t claim_token[16] = {0x98, 0xa8, 0x85, 0x6b, 0xa6, 0x53, 0x4b, 0xd5,
				   0x21, 0x21, 0x76, 0xb2, 0x2f, 0x3a, 0xcb, 0xb3};
	uint8_t data[1] = {0x00};
	struct ctr_cloud_packet pck;

	pck.serial_number = 2159017985;
	pck.sequence = 0;
	pck.flags = CTR_CLOUD_PACKET_FLAG_FIRST | CTR_CLOUD_PACKET_FLAG_LAST;
	pck.data_len = 1;
	pck.data = data;

	int ret = ctr_cloud_packet_pack(&pck, claim_token, &buffer);

	zassert_ok(ret, "ctr_cloud_packet_pack failed");
	zassert_equal(buffer.len, 15, "buffer.len not equal");

	char *expected = "3cd56e3ca930323680b00001c00000";

	uint8_t expectedBin[15];
	hex2bin(expected, strlen(expected), expectedBin, sizeof(expectedBin));

	zassert_equal(memcmp(buffer.mem, expectedBin, buffer.len), 0, "buffer.mem not equal");
}

ZTEST(subsus_ctr_cloud_0_packet, test_pack_c)
{
	CTR_BUF_DEFINE(buffer, CTR_CLOUD_PACKET_MAX_SIZE);
	ctr_buf_fill(&buffer, 0xff);

	uint8_t claim_token[16] = {0x98, 0xa8, 0x85, 0x6b, 0xa6, 0x53, 0x4b, 0xd5,
				   0x21, 0x21, 0x76, 0xb2, 0x2f, 0x3a, 0xcb, 0xb3};
	uint8_t data[] = {0x06, 0x43, 0xc8, 0xb2, 0x39};
	struct ctr_cloud_packet pck;

	pck.serial_number = 2159017985;
	pck.sequence = 0;
	pck.flags = CTR_CLOUD_PACKET_FLAG_FIRST;
	pck.data_len = 5;
	pck.data = data;

	int ret = ctr_cloud_packet_pack(&pck, claim_token, &buffer);

	zassert_ok(ret, "ctr_cloud_packet_pack failed");
	zassert_equal(buffer.len, 19, "buffer.len not equal");

	char *expected = "66df44241b89312280b0000180000643c8b239";

	uint8_t expectedBin[19];
	hex2bin(expected, strlen(expected), expectedBin, sizeof(expectedBin));

	zassert_equal(memcmp(buffer.mem, expectedBin, buffer.len), 0, "buffer.mem not equal");
}

ZTEST_SUITE(subsus_ctr_cloud_0_packet, NULL, NULL, NULL, NULL, NULL);
```
